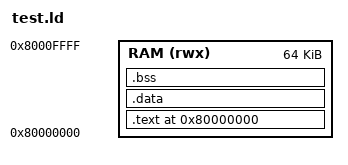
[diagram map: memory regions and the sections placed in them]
MEMORY {
    RAM (rwx) : ORIGIN = 0x80000000, LENGTH = 64K
}

SECTIONS {
    . = 0x80000000;

    .text : {
        *(.text.start)
        *(.text .text.*)
        *(.rodata .rodata.*)
    } > RAM

    .data : {
        *(.data .data.*)
        *(.sdata .sdata.*)
    } > RAM

    .bss : {
        *(.bss .bss.*)
        *(.sbss .sbss.*)
        *(COMMON)
    } > RAM
}

ENTRY(_start)
